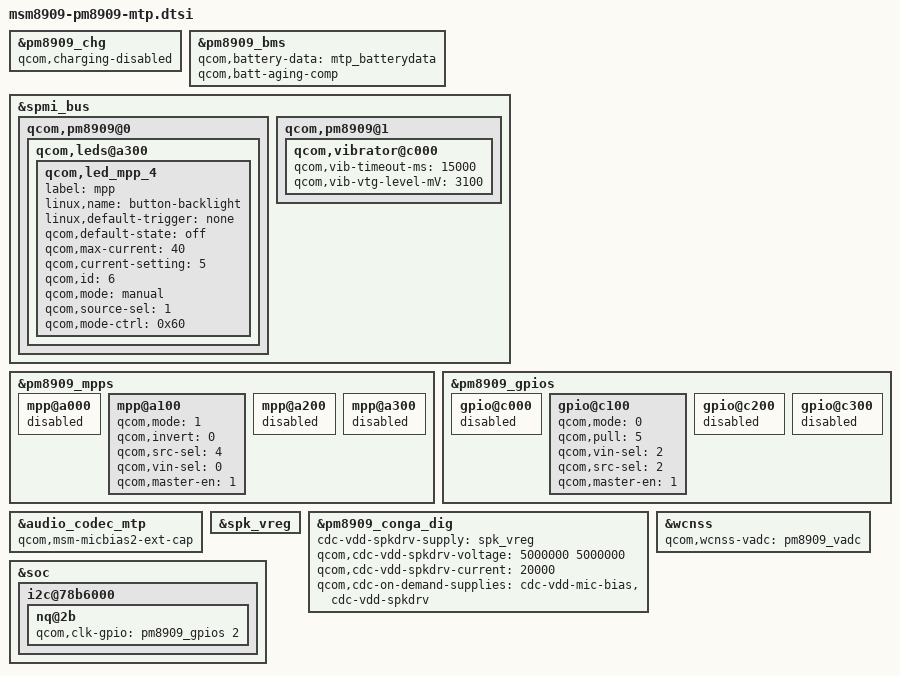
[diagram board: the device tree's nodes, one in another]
/*
 * Copyright (c) 2014-2015, The Linux Foundation. All rights reserved.
 *
 * This program is free software; you can redistribute it and/or modify
 * it under the terms of the GNU General Public License version 2 and
 * only version 2 as published by the Free Software Foundation.
 *
 * This program is distributed in the hope that it will be useful,
 * but WITHOUT ANY WARRANTY; without even the implied warranty of
 * MERCHANTABILITY or FITNESS FOR A PARTICULAR PURPOSE.  See the
 * GNU General Public License for more details.
 */

&pm8909_chg {
	status = "ok";
	qcom,charging-disabled;
};

&pm8909_bms {
	status = "ok";
	qcom,battery-data = <&mtp_batterydata>;
	qcom,batt-aging-comp;
};

&spmi_bus {
	qcom,pm8909@0 {
		qcom,leds@a300 {
			status = "okay";
			qcom,led_mpp_4 {
				label = "mpp";
				linux,name = "button-backlight";
				linux,default-trigger = "none";
				qcom,default-state = "off";
				qcom,max-current = <40>;
				qcom,current-setting = <5>;
				qcom,id = <6>;
				qcom,mode = "manual";
				qcom,source-sel = <1>;
				qcom,mode-ctrl = <0x60>;
			};
		};
	};

	qcom,pm8909@1 {
		qcom,vibrator@c000 {
			status = "okay";
			qcom,vib-timeout-ms = <15000>;
			qcom,vib-vtg-level-mV = <3100>;
		};
	};
};

&pm8909_mpps {
	mpp@a000 { /* MPP 1 */
		/* VDD_PX */
		status = "disabled";
	};

	mpp@a100 { /* MPP 2 */
		/* Backlight PWM */
		qcom,mode = <1>;		/* Digital output */
		qcom,invert = <0>;		/* Disable invert */
		qcom,src-sel = <4>;		/* DTEST1 */
		qcom,vin-sel = <0>;		/* VPH_PWR */
		qcom,master-en = <1>;		/* Enable MPP */
	};

	mpp@a200 { /* MPP 3 */
		/* VREF DAC */
		status = "disabled";
	};

	mpp@a300 { /* MPP 4 */
		/* HR LED */
		status = "disabled";
	};
};

&pm8909_gpios {
	gpio@c000 { /* GPIO 1 */
		/* Battery UICC Alarm */
		status = "disabled";
	};

	gpio@c100 { /* GPIO 2 */
		/* NFC_CLK_REQ */
		qcom,mode = <0>; /* QPNP_PIN_MODE_DIG_IN */
		qcom,pull = <5>; /* QPNP_PIN_PULL_NO */
		qcom,vin-sel = <2>; /* QPNP_PIN_VIN2 */
		qcom,src-sel = <2>; /* QPNP_PIN_SEL_FUNC_1 */
		qcom,master-en = <1>;
	};

	gpio@c200 { /* GPIO 3 */
		/* External regulator control for WTR */
		status = "disabled";
	};

	gpio@c300 { /* GPIO 4 */
		/* External regulator control for APC */
		status = "disabled";
	};
};

&audio_codec_mtp {
	qcom,msm-micbias2-ext-cap;
};

&spk_vreg {
	status = "okay";
};

&pm8909_conga_dig {
	cdc-vdd-spkdrv-supply = <&spk_vreg>;
	qcom,cdc-vdd-spkdrv-voltage = <5000000 5000000>;
	qcom,cdc-vdd-spkdrv-current = <20000>;
	qcom,cdc-on-demand-supplies = "cdc-vdd-mic-bias",
				      "cdc-vdd-spkdrv";
};

&wcnss {
	qcom,wcnss-vadc = <&pm8909_vadc>;
};

&soc {
	i2c@78b6000 {
			nq@2b {
			qcom,clk-gpio = <&pm8909_gpios 2 0>;
			};
	};

};
